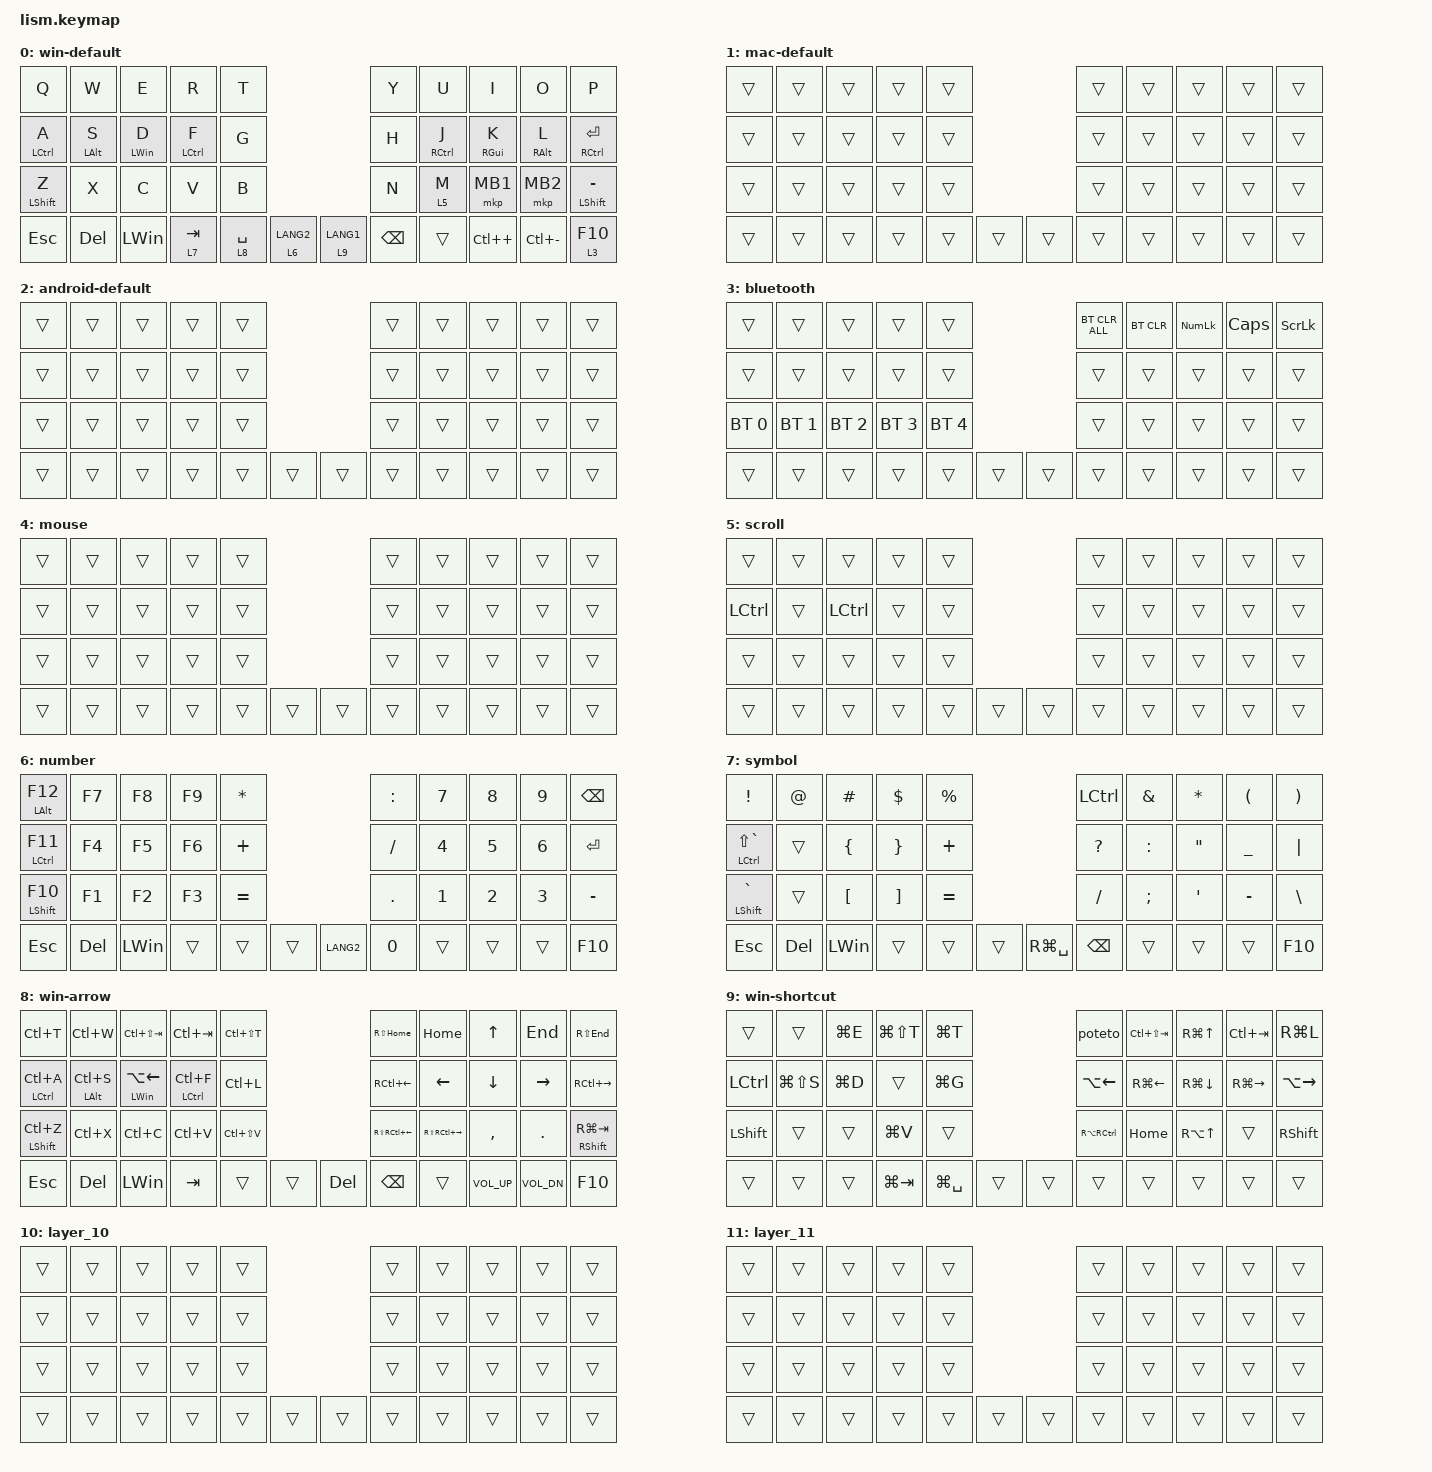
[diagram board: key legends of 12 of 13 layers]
#define ZMK_POINTING_DEFAULT_SCRL_VAL 200

#include <dt-bindings/zmk/mouse.h>
#include <behaviors.dtsi>
#include <dt-bindings/zmk/bt.h>
#include <dt-bindings/zmk/keys.h>
#include <dt-bindings/zmk/pointing.h>

&mt {
    tapping-term-ms = <300>;
    flavor = "balanced";
};

&lt { quick-tap-ms = <300>; };

/ {
    macros {
        emoji: emoji_macro {
            compatible = "zmk,behavior-macro";
            label = "EMOJI";
            #binding-cells = <0>;
            bindings =
                <&macro_press>,
                <&kp CAPSLOCK>,
                <&macro_tap>,
                <&kp E>,
                <&macro_release>,
                <&kp CAPSLOCK>;
        };

        poteto: poteto {
            compatible = "zmk,behavior-macro";
            #binding-cells = <0>;
            bindings = <&kp O &kp I &kp M &kp O &kp M &kp A &kp Z &kp I &kp P &kp O &kp T &kp E &kp T &kp O &kp N3 &kp AT &kp N8>;
            label = "POTETO";
        };
    };

    behaviors {
        encoder_msc: sensor_rotate_msc {
            compatible = "zmk,behavior-sensor-rotate-var";
            #sensor-binding-cells = <2>;
            bindings = <&msc>, <&msc>;

            tap-ms = <20>;
        };

        encoder_kp: sensor_rotate_kp {
            compatible = "zmk,behavior-sensor-rotate-var";
            #sensor-binding-cells = <2>;
            bindings = <&kp>, <&kp>;
        };
    };

    keymap {
        compatible = "zmk,keymap";

        win-default {
            display-name = "win-default";
            bindings = <
&kp Q             &kp W           &kp E           &kp R        &kp T                                    &kp Y          &kp U        &kp I            &kp O            &kp P
&mt LCTRL A       &mt LEFT_ALT S  &mt LEFT_WIN D  &mt LCTRL F  &kp G                                    &kp H          &mt RCTRL J  &mt RIGHT_GUI K  &mt RIGHT_ALT L  &mt RCTRL ENTER
&mt LEFT_SHIFT Z  &kp X           &kp C           &kp V        &kp B                                    &kp N          &lt 5 M      &mkp MB1         &mkp MB2         &mt LEFT_SHIFT MINUS
&kp ESC           &kp DEL         &kp LEFT_WIN    &lt 7 TAB    &lt 8 SPACE  &lt 6 LANG2    &lt 9 LANG1  &kp BACKSPACE  &trans       &kp LC(PLUS)     &kp LC(MINUS)    &lt 3 F10
            >;
        };

        mac-default {
            display-name = "mac-default";
            bindings = <
&trans  &trans  &trans  &trans  &trans                    &trans  &trans  &trans  &trans  &trans
&trans  &trans  &trans  &trans  &trans                    &trans  &trans  &trans  &trans  &trans
&trans  &trans  &trans  &trans  &trans                    &trans  &trans  &trans  &trans  &trans
&trans  &trans  &trans  &trans  &trans  &trans    &trans  &trans  &trans  &trans  &trans  &trans
            >;
        };

        android-default {
            display-name = "android-default";
            bindings = <
&trans  &trans  &trans  &trans  &trans                    &trans  &trans  &trans  &trans  &trans
&trans  &trans  &trans  &trans  &trans                    &trans  &trans  &trans  &trans  &trans
&trans  &trans  &trans  &trans  &trans                    &trans  &trans  &trans  &trans  &trans
&trans  &trans  &trans  &trans  &trans  &trans    &trans  &trans  &trans  &trans  &trans  &trans
            >;
        };

        bluetooth {
            display-name = "bluetooth";
            bindings = <
&trans        &trans        &trans        &trans        &trans                          &bt BT_CLR_ALL  &bt BT_CLR  &kp KP_NUMLOCK  &kp CAPSLOCK  &kp SCROLLLOCK
&trans        &trans        &trans        &trans        &trans                          &trans          &trans      &trans          &trans        &trans
&bt BT_SEL 0  &bt BT_SEL 1  &bt BT_SEL 2  &bt BT_SEL 3  &bt BT_SEL 4                    &trans          &trans      &trans          &trans        &trans
&trans        &trans        &trans        &trans        &trans        &trans    &trans  &trans          &trans      &trans          &trans        &trans
            >;
        };

        layer_4 {
            display-name = "mouse";
            bindings = <
&trans  &trans  &trans  &trans  &trans                    &trans  &trans  &trans  &trans  &trans
&trans  &trans  &trans  &trans  &trans                    &trans  &trans  &trans  &trans  &trans
&trans  &trans  &trans  &trans  &trans                    &trans  &trans  &trans  &trans  &trans
&trans  &trans  &trans  &trans  &trans  &trans    &trans  &trans  &trans  &trans  &trans  &trans
            >;
        };

        layer_5 {
            display-name = "scroll";
            bindings = <
&trans     &trans  &trans     &trans  &trans                    &trans  &trans  &trans  &trans  &trans
&kp LCTRL  &trans  &kp LCTRL  &trans  &trans                    &trans  &trans  &trans  &trans  &trans
&trans     &trans  &trans     &trans  &trans                    &trans  &trans  &trans  &trans  &trans
&trans     &trans  &trans     &trans  &trans  &trans    &trans  &trans  &trans  &trans  &trans  &trans
            >;
        };

        number {
            display-name = "number";
            bindings = <
&mt LEFT_ALT F12    &kp F7      &kp F8        &kp F9  &kp ASTERISK                       &kp COLON  &kp N7        &kp N8        &kp N9        &kp BACKSPACE
&mt LCTRL F11       &kp F4      &kp F5        &kp F6  &kp PLUS                           &kp SLASH  &kp NUMBER_4  &kp N5        &kp NUMBER_6  &kp ENTER
&mt LEFT_SHIFT F10  &kp F1      &kp F2        &kp F3  &kp EQUAL                          &kp DOT    &kp NUMBER_1  &kp NUMBER_2  &kp NUMBER_3  &kp MINUS
&kp ESC             &kp DELETE  &kp LEFT_WIN  &trans  &trans        &trans    &kp LANG2  &kp N0     &trans        &trans        &trans        &kp F10
            >;
        };

        symbol {
            display-name = "symbol";
            bindings = <
&kp EXCLAMATION       &kp AT_SIGN  &kp HASH          &kp DOLLAR         &kp PERCENT                           &kp LCTRL      &kp AMPERSAND  &kp ASTERISK       &kp LEFT_PARENTHESIS  &kp RIGHT_PARENTHESIS
&mt LCTRL LS(GRAVE)   &trans       &kp LEFT_BRACE    &kp RIGHT_BRACE    &kp PLUS                              &kp QUESTION   &kp COLON      &kp DOUBLE_QUOTES  &kp UNDERSCORE        &kp PIPE
&mt LEFT_SHIFT GRAVE  &trans       &kp LEFT_BRACKET  &kp RIGHT_BRACKET  &kp EQUAL                             &kp SLASH      &kp SEMICOLON  &kp SINGLE_QUOTE   &kp MINUS             &kp BACKSLASH
&kp ESCAPE            &kp DELETE   &kp LEFT_WIN      &trans             &trans       &trans    &kp RG(SPACE)  &kp BACKSPACE  &trans         &trans             &trans                &kp F10
            >;
        };

        win-arrow {
            display-name = "win-arrow";
            bindings = <
&kp LC(T)             &kp LC(W)           &kp LC(LS(TAB))        &kp LC(TAB)      &kp LC(LS(T))                        &kp RS(HOME)      &kp HOME           &kp UP_ARROW     &kp END          &kp RS(END)
&mt LCTRL LC(A)       &mt LEFT_ALT LC(S)  &mt LEFT_WIN LA(LEFT)  &mt LCTRL LC(F)  &kp LC(L)                            &kp RC(LEFT)      &kp LEFT_ARROW     &kp DOWN_ARROW   &kp RIGHT_ARROW  &kp RC(RIGHT)
&mt LEFT_SHIFT LC(Z)  &kp LC(X)           &kp LC(C)              &kp LC(V)        &kp LC(LS(V))                        &kp RS(RC(LEFT))  &kp RS(RC(RIGHT))  &kp COMMA        &kp PERIOD       &mt RIGHT_SHIFT RG(TAB)
&kp ESC               &kp DEL             &kp LEFT_WIN           &kp TAB          &trans         &trans    &kp DELETE  &kp BACKSPACE     &trans             &kp C_VOLUME_UP  &kp C_VOL_DN     &kp F10
            >;
        };

        win-shortcut {
            display-name = "win-shortcut";
            bindings = <
&trans          &trans         &kp LG(E)  &kp LG(LS(T))  &kp LG(T)                        &poteto        &kp LC(LS(TAB))  &kp RG(UP_ARROW)    &kp LC(TAB)    &kp RG(L)
&kp LCTRL       &kp LG(LS(S))  &kp LG(D)  &trans         &kp LG(G)                        &kp LA(LEFT)   &kp RG(LEFT)     &kp RG(DOWN_ARROW)  &kp RG(RIGHT)  &kp LA(RIGHT)
&kp LEFT_SHIFT  &trans         &trans     &kp LG(V)      &trans                           &kp RA(RCTRL)  &kp HOME         &kp RA(UP_ARROW)    &trans         &kp RSHFT
&trans          &trans         &trans     &kp LG(TAB)    &kp LG(SPACE)  &trans    &trans  &trans         &trans           &trans              &trans         &trans
            >;
        };

        layer_10 {
            bindings = <
&trans  &trans  &trans  &trans  &trans                    &trans  &trans  &trans  &trans  &trans
&trans  &trans  &trans  &trans  &trans                    &trans  &trans  &trans  &trans  &trans
&trans  &trans  &trans  &trans  &trans                    &trans  &trans  &trans  &trans  &trans
&trans  &trans  &trans  &trans  &trans  &trans    &trans  &trans  &trans  &trans  &trans  &trans
            >;
        };

        layer_11 {
            bindings = <
&trans  &trans  &trans  &trans  &trans                    &trans  &trans  &trans  &trans  &trans
&trans  &trans  &trans  &trans  &trans                    &trans  &trans  &trans  &trans  &trans
&trans  &trans  &trans  &trans  &trans                    &trans  &trans  &trans  &trans  &trans
&trans  &trans  &trans  &trans  &trans  &trans    &trans  &trans  &trans  &trans  &trans  &trans
            >;
        };

        layer_12 {
            bindings = <
&trans  &trans  &trans  &trans  &trans                    &trans  &trans  &trans  &trans  &trans
&trans  &trans  &trans  &trans  &trans                    &trans  &trans  &trans  &trans  &trans
&trans  &trans  &trans  &trans  &trans                    &trans  &trans  &trans  &trans  &trans
&trans  &trans  &trans  &trans  &trans  &trans    &trans  &trans  &trans  &trans  &trans  &trans
            >;
        };
    };
};
